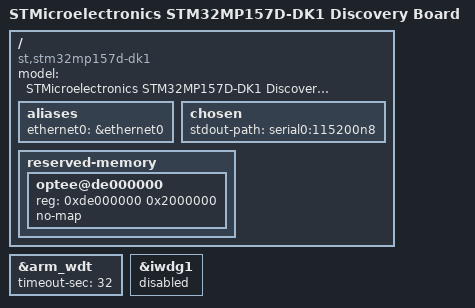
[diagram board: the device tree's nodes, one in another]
// SPDX-License-Identifier: (GPL-2.0-only OR BSD-3-Clause)
/*
 * Copyright (C) STMicroelectronics 2026 - All Rights Reserved
 * Author: Amelie Delaunay <amelie.delaunay@foss.st.com> for STMicroelectronics.
 */

/dts-v1/;

#include "stm32mp157.dtsi"
#include "stm32mp15xd.dtsi"
#include "stm32mp15-pinctrl.dtsi"
#include "stm32mp15xxac-pinctrl.dtsi"
#include "stm32mp15xx-dkx.dtsi"
#include "stm32mp157-scmi.dtsi"

/ {
	model = "STMicroelectronics STM32MP157D-DK1 Discovery Board";
	compatible = "st,stm32mp157d-dk1", "st,stm32mp157";

	aliases {
		ethernet0 = &ethernet0;
	};

	chosen {
		stdout-path = "serial0:115200n8";
	};

	reserved-memory {
		optee@de000000 {
			reg = <0xde000000 0x2000000>;
			no-map;
		};
	};
};

&arm_wdt {
	timeout-sec = <32>;
	bootph-all;
	status = "okay";
};

&iwdg1 {
	/* IWDG1 is secure and managed through arm_wdt */
	status = "disabled";
};
